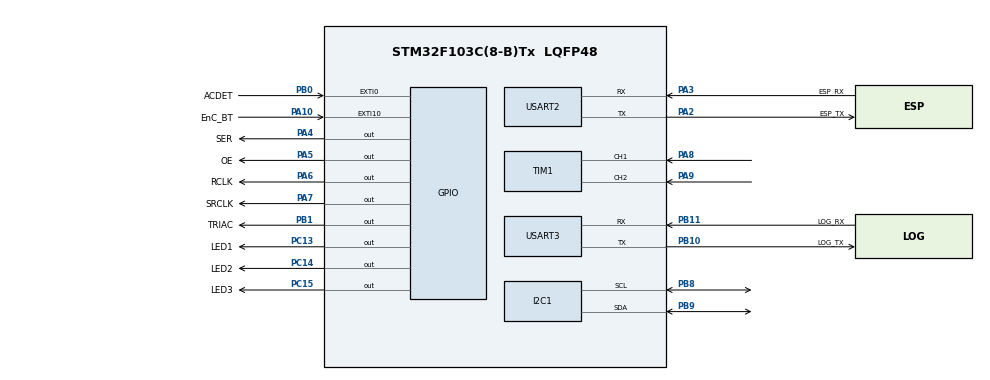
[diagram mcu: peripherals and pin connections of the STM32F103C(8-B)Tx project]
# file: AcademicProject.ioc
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Mcu.Family=STM32F1
Mcu.Name=STM32F103C(8-B)Tx
Mcu.Package=LQFP48
NVIC.EXTI0_IRQn=true\:0\:0\:false\:false\:true\:true\:true\:true
NVIC.EXTI15_10_IRQn=true\:0\:0\:false\:false\:true\:true\:true\:true
NVIC.I2C1_EV_IRQn=true\:0\:0\:false\:false\:true\:true\:true\:true
NVIC.PriorityGroup=NVIC_PRIORITYGROUP_4
NVIC.TIM1_UP_IRQn=true\:0\:0\:false\:false\:true\:true\:true\:true
NVIC.TIM4_IRQn=true\:0\:0\:false\:false\:true\:true\:true\:true
PA10.GPIO_Label=EnC_BT
PA10.Signal=GPXTI10
PA13.Mode=Serial_Wire
PA13.Signal=SYS_JTMS-SWDIO
PA14.Mode=Serial_Wire
PA14.Signal=SYS_JTCK-SWCLK
PA2.GPIO_Label=ESP_TX
PA2.Mode=Asynchronous
PA2.Signal=USART2_TX
PA3.GPIO_Label=ESP_RX
PA3.Mode=Asynchronous
PA3.Signal=USART2_RX
PA4.GPIO_Label=SER
PA4.GPIO_ModeDefaultOutputPP=GPIO_MODE_OUTPUT_OD
PA4.GPIO_PuPd=GPIO_NOPULL
PA4.GPIO_Speed=GPIO_SPEED_FREQ_HIGH
PA4.Signal=GPIO_Output
PA5.GPIO_Label=OE
PA5.GPIO_ModeDefaultOutputPP=GPIO_MODE_OUTPUT_OD
PA5.GPIO_PuPd=GPIO_NOPULL
PA5.GPIO_Speed=GPIO_SPEED_FREQ_HIGH
PA5.Signal=GPIO_Output
PA6.GPIO_Label=RCLK
PA6.GPIO_ModeDefaultOutputPP=GPIO_MODE_OUTPUT_OD
PA6.GPIO_PuPd=GPIO_NOPULL
PA6.GPIO_Speed=GPIO_SPEED_FREQ_HIGH
PA6.Signal=GPIO_Output
PA7.GPIO_Label=SRCLK
PA7.GPIO_ModeDefaultOutputPP=GPIO_MODE_OUTPUT_OD
PA7.GPIO_PuPd=GPIO_NOPULL
PA7.GPIO_Speed=GPIO_SPEED_FREQ_HIGH
PA7.Signal=GPIO_Output
PA8.Signal=S_TIM1_CH1
PA9.Signal=S_TIM1_CH2
PB0.GPIO_Label=ACDET
PB0.GPIO_ModeDefaultEXTI=GPIO_MODE_IT_FALLING
PB0.Signal=GPXTI0
PB1.GPIO_Label=TRIAC
PB1.GPIO_Speed=GPIO_SPEED_FREQ_HIGH
PB1.Signal=GPIO_Output
PB10.GPIO_Label=LOG_TX
PB10.Mode=Asynchronous
PB10.Signal=USART3_TX
PB11.GPIO_Label=LOG_RX
PB11.Mode=Asynchronous
PB11.Signal=USART3_RX
PB8.Mode=I2C
PB8.Signal=I2C1_SCL
PB9.Mode=I2C
PB9.Signal=I2C1_SDA
PC13-TAMPER-RTC.GPIO_Label=LED1
PC13-TAMPER-RTC.GPIO_Speed=GPIO_SPEED_FREQ_HIGH
PC13-TAMPER-RTC.PinState=GPIO_PIN_SET
PC13-TAMPER-RTC.Signal=GPIO_Output
PC14-OSC32_IN.GPIO_Label=LED2
PC14-OSC32_IN.GPIO_Speed=GPIO_SPEED_FREQ_HIGH
PC14-OSC32_IN.PinState=GPIO_PIN_SET
PC14-OSC32_IN.Signal=GPIO_Output
PC15-OSC32_OUT.GPIO_Label=LED3
PC15-OSC32_OUT.GPIO_Speed=GPIO_SPEED_FREQ_HIGH
PC15-OSC32_OUT.PinState=GPIO_PIN_SET
PC15-OSC32_OUT.Signal=GPIO_Output
PD0-OSC_IN.Mode=HSE-External-Oscillator
PD0-OSC_IN.Signal=RCC_OSC_IN
PD1-OSC_OUT.Mode=HSE-External-Oscillator
PD1-OSC_OUT.Signal=RCC_OSC_OUT
ProjectManager.HeapSize=0x200
ProjectManager.StackSize=0x400
ProjectManager.TargetToolchain=STM32CubeIDE
RCC.APB1Freq_Value=8000000
RCC.APB2Freq_Value=8000000
SH.S_TIM1_CH1.0=TIM1_CH1,Encoder_Interface
SH.S_TIM1_CH2.0=TIM1_CH2,Encoder_Interface
TIM1.EncoderMode=TIM_ENCODERMODE_TI12
TIM4.Period=10000 - 1
TIM4.Prescaler=72 - 1
USART2.VirtualMode=VM_ASYNC
USART3.VirtualMode=VM_ASYNC
VP_TIM4_VS_ClockSourceINT.Mode=Internal
board=custom

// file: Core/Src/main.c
/* USER CODE BEGIN Header */
/**
  ******************************************************************************
  * @file           : main.c
  * @brief          : Main program body
  ******************************************************************************
  * @attention
  *
  * Copyright (c) 2023 STMicroelectronics.
  * All rights reserved.
  *
  * This software is licensed under terms that can be found in the LICENSE file
  * in the root directory of this software component.
  * If no LICENSE file comes with this software, it is provided AS-IS.
  *
  ******************************************************************************
  */
/* USER CODE END Header */
#include "main.h"

/* USER CODE BEGIN Includes */
#include "74HC595.h"

/* USER CODE END Includes */

I2C_HandleTypeDef hi2c1;

TIM_HandleTypeDef htim1;
TIM_HandleTypeDef htim4;

UART_HandleTypeDef huart2;
UART_HandleTypeDef huart3;

void SystemClock_Config(void);
static void MX_GPIO_Init(void);
static void MX_I2C1_Init(void);
static void MX_TIM1_Init(void);
static void MX_USART2_UART_Init(void);
static void MX_USART3_UART_Init(void);
static void MX_TIM4_Init(void);

int main(void)
{

  /* MCU Configuration--------------------------------------------------------*/

  /* Reset of all peripherals, Initializes the Flash interface and the Systick. */
  HAL_Init();

  /* Configure the system clock */
  SystemClock_Config();

  /* Initialize all configured peripherals */
  MX_GPIO_Init();
  MX_I2C1_Init();
  MX_TIM1_Init();
  MX_USART2_UART_Init();
  MX_USART3_UART_Init();
  MX_TIM4_Init();

  /* Infinite loop */
  while (1)
  {

  }
}

void SystemClock_Config(void)
{
  RCC_OscInitTypeDef RCC_OscInitStruct = {0};
  RCC_ClkInitTypeDef RCC_ClkInitStruct = {0};

  /** Initializes the RCC Oscillators according to the specified parameters
  * in the RCC_OscInitTypeDef structure.
  */
  RCC_OscInitStruct.OscillatorType = RCC_OSCILLATORTYPE_HSI;
  RCC_OscInitStruct.HSIState = RCC_HSI_ON;
  RCC_OscInitStruct.HSICalibrationValue = RCC_HSICALIBRATION_DEFAULT;
  RCC_OscInitStruct.PLL.PLLState = RCC_PLL_NONE;
  if (HAL_RCC_OscConfig(&RCC_OscInitStruct) != HAL_OK)
  {
    Error_Handler();
  }

  /** Initializes the CPU, AHB and APB buses clocks
  */
  RCC_ClkInitStruct.ClockType = RCC_CLOCKTYPE_HCLK|RCC_CLOCKTYPE_SYSCLK
                              |RCC_CLOCKTYPE_PCLK1|RCC_CLOCKTYPE_PCLK2;
  RCC_ClkInitStruct.SYSCLKSource = RCC_SYSCLKSOURCE_HSI;
  RCC_ClkInitStruct.AHBCLKDivider = RCC_SYSCLK_DIV1;
  RCC_ClkInitStruct.APB1CLKDivider = RCC_HCLK_DIV1;
  RCC_ClkInitStruct.APB2CLKDivider = RCC_HCLK_DIV1;

  if (HAL_RCC_ClockConfig(&RCC_ClkInitStruct, FLASH_LATENCY_0) != HAL_OK)
  {
    Error_Handler();
  }
}

static void MX_I2C1_Init(void)
{

  hi2c1.Instance = I2C1;
  hi2c1.Init.ClockSpeed = 100000;
  hi2c1.Init.DutyCycle = I2C_DUTYCYCLE_2;
  hi2c1.Init.OwnAddress1 = 0;
  hi2c1.Init.AddressingMode = I2C_ADDRESSINGMODE_7BIT;
  hi2c1.Init.DualAddressMode = I2C_DUALADDRESS_DISABLE;
  hi2c1.Init.OwnAddress2 = 0;
  hi2c1.Init.GeneralCallMode = I2C_GENERALCALL_DISABLE;
  hi2c1.Init.NoStretchMode = I2C_NOSTRETCH_DISABLE;
  if (HAL_I2C_Init(&hi2c1) != HAL_OK)
  {
    Error_Handler();
  }

}

static void MX_TIM1_Init(void)
{

  TIM_Encoder_InitTypeDef sConfig = {0};
  TIM_MasterConfigTypeDef sMasterConfig = {0};

  htim1.Instance = TIM1;
  htim1.Init.Prescaler = 0;
  htim1.Init.CounterMode = TIM_COUNTERMODE_UP;
  htim1.Init.Period = 65535;
  htim1.Init.ClockDivision = TIM_CLOCKDIVISION_DIV1;
  htim1.Init.RepetitionCounter = 0;
  htim1.Init.AutoReloadPreload = TIM_AUTORELOAD_PRELOAD_DISABLE;
  sConfig.EncoderMode = TIM_ENCODERMODE_TI12;
  sConfig.IC1Polarity = TIM_ICPOLARITY_RISING;
  sConfig.IC1Selection = TIM_ICSELECTION_DIRECTTI;
  sConfig.IC1Prescaler = TIM_ICPSC_DIV1;
  sConfig.IC1Filter = 0;
  sConfig.IC2Polarity = TIM_ICPOLARITY_RISING;
  sConfig.IC2Selection = TIM_ICSELECTION_DIRECTTI;
  sConfig.IC2Prescaler = TIM_ICPSC_DIV1;
  sConfig.IC2Filter = 0;
  if (HAL_TIM_Encoder_Init(&htim1, &sConfig) != HAL_OK)
  {
    Error_Handler();
  }
  sMasterConfig.MasterOutputTrigger = TIM_TRGO_RESET;
  sMasterConfig.MasterSlaveMode = TIM_MASTERSLAVEMODE_DISABLE;
  if (HAL_TIMEx_MasterConfigSynchronization(&htim1, &sMasterConfig) != HAL_OK)
  {
    Error_Handler();
  }

}

static void MX_TIM4_Init(void)
{

  TIM_ClockConfigTypeDef sClockSourceConfig = {0};
  TIM_MasterConfigTypeDef sMasterConfig = {0};

  htim4.Instance = TIM4;
  htim4.Init.Prescaler = 72 - 1;
  htim4.Init.CounterMode = TIM_COUNTERMODE_UP;
  htim4.Init.Period = 10000 - 1;
  htim4.Init.ClockDivision = TIM_CLOCKDIVISION_DIV1;
  htim4.Init.AutoReloadPreload = TIM_AUTORELOAD_PRELOAD_DISABLE;
  if (HAL_TIM_Base_Init(&htim4) != HAL_OK)
  {
    Error_Handler();
  }
  sClockSourceConfig.ClockSource = TIM_CLOCKSOURCE_INTERNAL;
  if (HAL_TIM_ConfigClockSource(&htim4, &sClockSourceConfig) != HAL_OK)
  {
    Error_Handler();
  }
  sMasterConfig.MasterOutputTrigger = TIM_TRGO_RESET;
  sMasterConfig.MasterSlaveMode = TIM_MASTERSLAVEMODE_DISABLE;
  if (HAL_TIMEx_MasterConfigSynchronization(&htim4, &sMasterConfig) != HAL_OK)
  {
    Error_Handler();
  }

}

static void MX_USART2_UART_Init(void)
{

  huart2.Instance = USART2;
  huart2.Init.BaudRate = 115200;
  huart2.Init.WordLength = UART_WORDLENGTH_8B;
  huart2.Init.StopBits = UART_STOPBITS_1;
  huart2.Init.Parity = UART_PARITY_NONE;
  huart2.Init.Mode = UART_MODE_TX_RX;
  huart2.Init.HwFlowCtl = UART_HWCONTROL_NONE;
  huart2.Init.OverSampling = UART_OVERSAMPLING_16;
  if (HAL_UART_Init(&huart2) != HAL_OK)
  {
    Error_Handler();
  }

}

static void MX_USART3_UART_Init(void)
{

  huart3.Instance = USART3;
  huart3.Init.BaudRate = 115200;
  huart3.Init.WordLength = UART_WORDLENGTH_8B;
  huart3.Init.StopBits = UART_STOPBITS_1;
  huart3.Init.Parity = UART_PARITY_NONE;
  huart3.Init.Mode = UART_MODE_TX_RX;
  huart3.Init.HwFlowCtl = UART_HWCONTROL_NONE;
  huart3.Init.OverSampling = UART_OVERSAMPLING_16;
  if (HAL_UART_Init(&huart3) != HAL_OK)
  {
    Error_Handler();
  }

}

static void MX_GPIO_Init(void)
{
  GPIO_InitTypeDef GPIO_InitStruct = {0};

  /* GPIO Ports Clock Enable */
  __HAL_RCC_GPIOC_CLK_ENABLE();
  __HAL_RCC_GPIOD_CLK_ENABLE();
  __HAL_RCC_GPIOA_CLK_ENABLE();
  __HAL_RCC_GPIOB_CLK_ENABLE();

  /*Configure GPIO pin Output Level */
  HAL_GPIO_WritePin(GPIOC, LED1_Pin|LED2_Pin|LED3_Pin, GPIO_PIN_SET);

  /*Configure GPIO pin Output Level */
  HAL_GPIO_WritePin(GPIOA, SER_Pin|OE_Pin|RCLK_Pin|SRCLK_Pin, GPIO_PIN_RESET);

  /*Configure GPIO pin Output Level */
  HAL_GPIO_WritePin(TRIAC_GPIO_Port, TRIAC_Pin, GPIO_PIN_RESET);

  /*Configure GPIO pins : LED1_Pin LED2_Pin LED3_Pin */
  GPIO_InitStruct.Pin = LED1_Pin|LED2_Pin|LED3_Pin;
  GPIO_InitStruct.Mode = GPIO_MODE_OUTPUT_PP;
  GPIO_InitStruct.Pull = GPIO_NOPULL;
  GPIO_InitStruct.Speed = GPIO_SPEED_FREQ_HIGH;
  HAL_GPIO_Init(GPIOC, &GPIO_InitStruct);

  /*Configure GPIO pins : SER_Pin OE_Pin RCLK_Pin SRCLK_Pin */
  GPIO_InitStruct.Pin = SER_Pin|OE_Pin|RCLK_Pin|SRCLK_Pin;
  GPIO_InitStruct.Mode = GPIO_MODE_OUTPUT_OD;
  GPIO_InitStruct.Pull = GPIO_NOPULL;
  GPIO_InitStruct.Speed = GPIO_SPEED_FREQ_HIGH;
  HAL_GPIO_Init(GPIOA, &GPIO_InitStruct);

  /*Configure GPIO pin : ACDET_Pin */
  GPIO_InitStruct.Pin = ACDET_Pin;
  GPIO_InitStruct.Mode = GPIO_MODE_IT_FALLING;
  GPIO_InitStruct.Pull = GPIO_NOPULL;
  HAL_GPIO_Init(ACDET_GPIO_Port, &GPIO_InitStruct);

  /*Configure GPIO pin : TRIAC_Pin */
  GPIO_InitStruct.Pin = TRIAC_Pin;
  GPIO_InitStruct.Mode = GPIO_MODE_OUTPUT_PP;
  GPIO_InitStruct.Pull = GPIO_NOPULL;
  GPIO_InitStruct.Speed = GPIO_SPEED_FREQ_HIGH;
  HAL_GPIO_Init(TRIAC_GPIO_Port, &GPIO_InitStruct);

  /*Configure GPIO pin : EnC_BT_Pin */
  GPIO_InitStruct.Pin = EnC_BT_Pin;
  GPIO_InitStruct.Mode = GPIO_MODE_IT_RISING;
  GPIO_InitStruct.Pull = GPIO_NOPULL;
  HAL_GPIO_Init(EnC_BT_GPIO_Port, &GPIO_InitStruct);

  /* EXTI interrupt init*/
  HAL_NVIC_SetPriority(EXTI0_IRQn, 0, 0);
  HAL_NVIC_EnableIRQ(EXTI0_IRQn);

  HAL_NVIC_SetPriority(EXTI15_10_IRQn, 0, 0);
  HAL_NVIC_EnableIRQ(EXTI15_10_IRQn);

}

void Error_Handler(void)
{
  __disable_irq();
  while (1)
  {
  }
}
